# PIC32CM5112SG00100 device description
Architecture: CORTEX-M23; Family: PIC32CM; Series: PIC32CMSG00
Registers are 32-bit, read-write, reset 0x0 unless marked. A register's access mark holds for its fields unless they carry their own. Offsets are from the block's base; [hi:lo] are bit positions.

## HSM — Cryptographic Acceleration Module Lite
Instances: HSM 0x4F000000
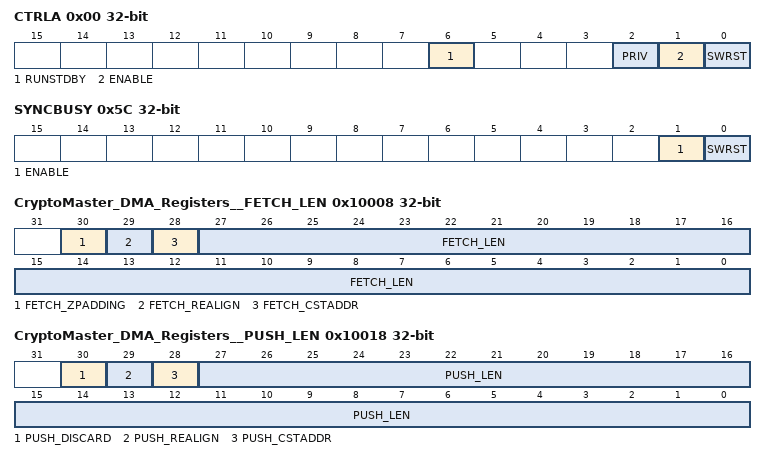
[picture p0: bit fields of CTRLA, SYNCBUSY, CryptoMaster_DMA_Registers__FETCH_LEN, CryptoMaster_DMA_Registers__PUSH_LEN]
0x00 CTRLA — Control Register A
  [6] RUNSTDBY — Run In Standby bit
    0=HSM clock is disabled in Standby Sleep mode, clock requests are de-asserted after any pending bus transactions or requests are completed; 1=If enabled, the HSM clock remains requested in Standby Sleep mode
  [2] PRIV — Privileged Access Only - This bit affects all Wrapper and EIP registers.
    0=HSM registers accessible in privileged and unprivileged modes. Master Requests are NOT privileged; 1=HSM registers only accessible in privileged mode. Master Requests are also privileged.
  [1] ENABLE — Macro/Clock Enable bit
    0=HSM clock is not requested and macros is disabled; 1=HSM clock is requested and macro is enabled
  [0] SWRST — Software Reset1 = Reset registers and internal state0 = No effect
0x38 STATUSA ro — STATUS Register A
  [0] OTPLOCK — OTP Lock bit
    1=OTP lock bit set. Device not in IC manufacturing.
0x5C SYNCBUSY ro
  [1] ENABLE — Macro Enable Synchronization Busy
    0=ENABLE synchronization is NOT busy; 1=ENABLE synchronization is busy
  [0] SWRST — Software Reset Synchronization Busy1 = SWRST synchronization is busy0 = SWRST synchronization is NOT busy
0x10000 CryptoMaster_DMA_Registers__FETCH_ADDR_LSB
  [31:0] FETCH_ADDR_LSB
0x10004 CryptoMaster_DMA_Registers__FETCH_ADDR_MSB
  [31:0] FETCH_ADDR_MSB
0x10008 CryptoMaster_DMA_Registers__FETCH_LEN
  [30] FETCH_ZPADDING, [29] FETCH_REALIGN, [28] FETCH_CSTADDR, [27:0] FETCH_LEN
0x1000C CryptoMaster_DMA_Registers__FETCH_TAG
  [31:0] FETCH_TAG
0x10010 CryptoMaster_DMA_Registers__PUSH_ADDR_LSB
  [31:0] PUSH_ADDR_LSB
0x10014 CryptoMaster_DMA_Registers__PUSH_ADDR_MSB
  [31:0] PUSH_ADDR_MSB
0x10018 CryptoMaster_DMA_Registers__PUSH_LEN
  [30] PUSH_DISCARD, [29] PUSH_REALIGN, [28] PUSH_CSTADDR, [27:0] PUSH_LEN
0x1001C CryptoMaster_DMA_Registers__INT_EN
  [5:0] INT_EN
0x10020 CryptoMaster_DMA_Registers__INT_ENSET wo (atomic set of CryptoMaster_DMA_Registers__INT_EN)
  [5:0] INT_ENSET
0x10024 CryptoMaster_DMA_Registers__INT_ENCLR wo (atomic clear of CryptoMaster_DMA_Registers__INT_EN)
  [5:0] INT_ENCLR
0x10028 CryptoMaster_DMA_Registers__INT_STATRAW ro
  [5:0] INT_STATRAW
0x1002C CryptoMaster_DMA_Registers__INT_STAT ro
  [5:0] INT_STAT
0x10030 CryptoMaster_DMA_Registers__INT_STATCLR wo (atomic clear of CryptoMaster_DMA_Registers__INT_STAT)
  [5:0] INT_STATCLR
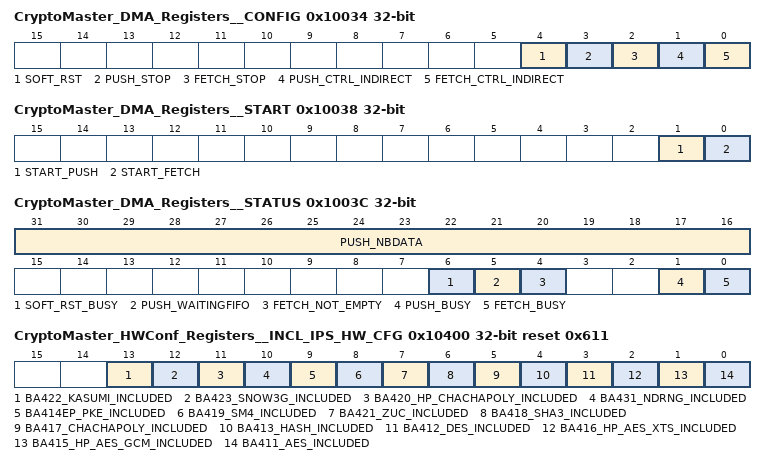
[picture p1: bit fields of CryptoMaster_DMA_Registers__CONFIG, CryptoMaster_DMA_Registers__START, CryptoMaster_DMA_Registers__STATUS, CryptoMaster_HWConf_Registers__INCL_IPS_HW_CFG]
0x10034 CryptoMaster_DMA_Registers__CONFIG
  [4] SOFT_RST, [3] PUSH_STOP, [2] FETCH_STOP, [1] PUSH_CTRL_INDIRECT, [0] FETCH_CTRL_INDIRECT
0x10038 CryptoMaster_DMA_Registers__START wo
  [1] START_PUSH, [0] START_FETCH
0x1003C CryptoMaster_DMA_Registers__STATUS ro
  [31:16] PUSH_NBDATA, [6] SOFT_RST_BUSY, [5] PUSH_WAITINGFIFO, [4] FETCH_NOT_EMPTY, [1] PUSH_BUSY, [0] FETCH_BUSY
0x10400 CryptoMaster_HWConf_Registers__INCL_IPS_HW_CFG ro reset 0x611
  [13] BA422_KASUMI_INCLUDED — Generic g_IncludeKasumi value. BA422-Kasumi IP included if set
  [12] BA423_SNOW3G_INCLUDED — Generic g_IncludeSnow3G value. BA423-Snow3G IP included if set
  [11] BA420_HP_CHACHAPOLY_INCLUDED — Generic g_IncludeHPChachaPoly value. BA420-HP-ChaChaPoly IP included if set
  [10] BA431_NDRNG_INCLUDED — Generic g_IncludeNDRNG value. BA431-NDRNG IP included if set
  [9] BA414EP_PKE_INCLUDED — Generic g_IncludePKE value. BA414EP-PKE IP included if set
  [8] BA419_SM4_INCLUDED — Generic g_IncludeSM4 value. BA419-SM4 IP included if set
  [7] BA421_ZUC_INCLUDED — Generic g_IncludeZUC value. BA421-ZUC IP included if set
  [6] BA418_SHA3_INCLUDED — Generic g_IncludeSHA3 value. BA418-SHA3 IP included if set
  [5] BA417_CHACHAPOLY_INCLUDED — Generic g_IncludeChachaPoly value. BA417-ChaChaPoly IP included if set
  [4] BA413_HASH_INCLUDED — Generic g_IncludeHASH value. BA413-HASH IP included if set
  [3] BA412_DES_INCLUDED — Generic g_IncludeDES value. BA412-3DES IP included if set
  [2] BA416_HP_AES_XTS_INCLUDED — Generic g_IncludeAESXTS value. BA416-HP-AES-XTS IP included if set
  [1] BA415_HP_AES_GCM_INCLUDED — Generic g_IncludeAESGCM value. BA415-HP-AES-GCM IP included if set
  [0] BA411_AES_INCLUDED — Generic g_IncludeAES value. BA411E-AES IP included if set
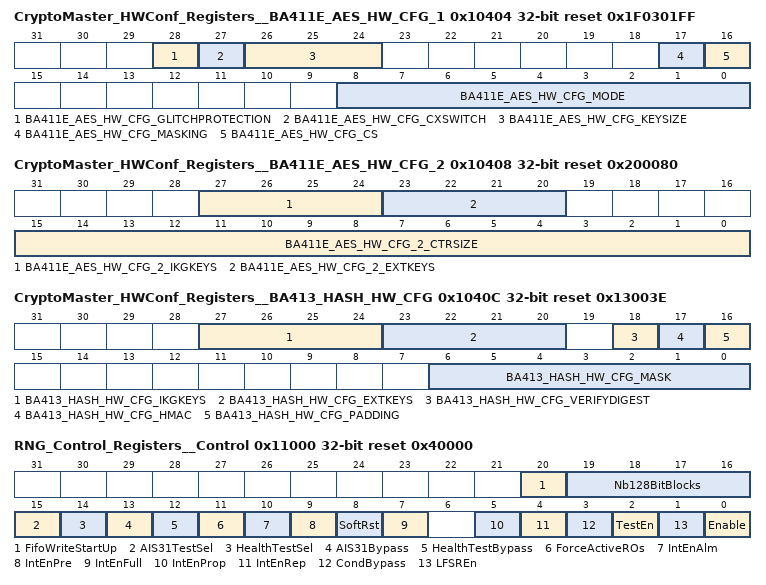
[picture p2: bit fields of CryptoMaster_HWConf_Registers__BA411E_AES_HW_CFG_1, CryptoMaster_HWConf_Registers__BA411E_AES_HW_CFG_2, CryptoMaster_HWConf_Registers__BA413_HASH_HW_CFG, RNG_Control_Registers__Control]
0x10404 CryptoMaster_HWConf_Registers__BA411E_AES_HW_CFG_1 ro reset 0x1F0301FF
  [28] BA411E_AES_HW_CFG_GLITCHPROTECTION — Generic g_GlitchProtection value. BA411E-AES engine configuration.
  [27] BA411E_AES_HW_CFG_CXSWITCH — Generic g_CxSwitch value. BA411E-AES engine configuration.
  [26:24] BA411E_AES_HW_CFG_KEYSIZE — Generic g_Keysize value. BA411E-AES engine configuration.
  [17] BA411E_AES_HW_CFG_MASKING — Generic g_UseMasking value. BA411E-AES engine configuration.
  [16] BA411E_AES_HW_CFG_CS — Generic g_CS value. BA411E-AES engine configuration.
  [8:0] BA411E_AES_HW_CFG_MODE — Generic g_AesModesPoss value. BA411E-AES engine configuration.
0x10408 CryptoMaster_HWConf_Registers__BA411E_AES_HW_CFG_2 ro reset 0x200080 — Generic g_CtrSize value. BA411E-AES engine configuration.
  [27:24] BA411E_AES_HW_CFG_2_IKGKEYS — Generic g_IKG_nb_AES_keys value. BA411E-AES engine configuration.
  [23:20] BA411E_AES_HW_CFG_2_EXTKEYS — Generic g_Ext_nb_AES_keys value. BA411E-AES engine configuration.
  [15:0] BA411E_AES_HW_CFG_2_CTRSIZE — Generic g_CtrSize value. BA411E-AES engine configuration.
0x1040C CryptoMaster_HWConf_Registers__BA413_HASH_HW_CFG ro reset 0x13003E
  [27:24] BA413_HASH_HW_CFG_IKGKEYS — Generic g_IKG_nb_Hash_keys value. BA413-Hash engine configuration.
  [23:20] BA413_HASH_HW_CFG_EXTKEYS — Generic g_Ext_nb_Hash_keys value. BA413-Hash engine configuration.
  [18] BA413_HASH_HW_CFG_VERIFYDIGEST — Generic g_HashVerifyDigest value. BA413-Hash engine configuration.
  [17] BA413_HASH_HW_CFG_HMAC — Generic g_HMAC_enabled value. BA413-Hash engine configuration.
  [16] BA413_HASH_HW_CFG_PADDING — Generic g_HashPadding value. BA413-Hash engine configuration.
  [6:0] BA413_HASH_HW_CFG_MASK — Generic g_HashMaskFunc value. BA413-Hash engine configuration.
0x10410 CryptoMaster_HWConf_Registers__BA418_SHA3_HW_CFG ro — Generic g_Sha3CtxtEn value. BA418-SHA3 configuration.
  [0] BA418_SHA3_HW_CFG
0x10414 CryptoMaster_HWConf_Registers__BA419_SM4_HW_CFG ro reset 0x1FF — Generic g_SM4ModesPoss value. BA419-SM4 engine configuration.
  [8:0] BA419_SM4_HW_CFG
0x10418 CryptoMaster_HWConf_Registers__BA424_ARIA_HW_CFG ro reset 0x17F — Generic g_aria_modePoss value. BA424-Aria engine configuration.
  [8:0] BA424_ARIA_HW_CFG
0x11000 RNG_Control_Registers__Control reset 0x40000 — Control register
  [20] FifoWriteStartUp — Enable write of the samples in the FIFO during start-up.
  [19:16] Nb128BitBlocks — Number of 128 bit blocks used in AES-CBCMAC post-processing. This value cannot be zero.
  [15] AIS31TestSel — Select input to the AIS31 test module: 0: Before conditioning, 1: After conditioning.
  [14] HealthTestSel — Select input to health test module: 0: Before conditioning, 1: After conditioning.
  [13] AIS31Bypass — Bypass AIS31 tests such that the results of the start-up and online tests do not affect the FSM state.
  [12] HealthTestBypass — Bypass NIST tests such that the results of the start-up and online test do not affect the FSM state.
  [11] ForceActiveROs — Force oscillators to run when FIFO is full.
  [10] IntEnAlm — Interrupt enable for AIS31 noise alarm.
  [9] IntEnPre — Interrupt enable for AIS31 preliminary noise alarm.
  [8] SoftRst — Software reset: 0: Normal mode, 1: The continuous test, the conditioning function and the FIFO are reset. This bit is not cleared automatically.
  [7] IntEnFull — Interrupt enable for FIFO full.
  [5] IntEnProp — Interrupt enable for Adaptive Proportion Test failure (1024-sample window).
  [4] IntEnRep — Interrupt enable for Repetition Count Test failure.
  [3] CondBypass — 0: the conditioning function is used (normal mode), 1: the conditioning function is bypassed (to observe entropy source directly).
  [2] TestEn — Select input for conditioning function and continuous tests: 0: Noise source (normal mode), 1: Test data register (test mode).
  [1] LFSREn — Select between the NDRNG with asynchronous free running oscillators (when '0') and the Pseudo-Random generator with synchronous oscillators for simulation purpose (when '1').
  [0] Enable — Enable the NDRNG.
0x11004 RNG_Control_Registers__FIFOLevel — FIFO level register.
  [31:0] FIFOLevel — Number of 32 bits words of random available in the FIFO. Any write to this register clears the FullInt flag in the Status register.
0x11008 RNG_Control_Registers__FIFOThreshold reset 0x1 — FIFO threshold register.
  [1:0] FIFOThreshold — FIFO level below which the module leaves the idle state to refill the FIFO, expressed in number of 128bit blocks.
0x1100C RNG_Control_Registers__FIFODepth ro reset 0x8 — FIFO depth register.
  [31:0] FIFODepth — Maximum number of 32 bits words that can be stored in the FIFO: 2**g_fifodepth.
0x11010 RNG_Control_Registers__Key0 — Key register (MSB).
0x11014 RNG_Control_Registers__Key1 — Key register.
0x11018 RNG_Control_Registers__Key2 — Key register.
0x1101C RNG_Control_Registers__Key3 — Key register (LSB).
0x11020 RNG_Control_Registers__TestData wo — Test data register.
0x11024 RNG_Control_Registers__RepeatThreshold reset 0x29 — Repetition Test Count Cut-Off value.
  [5:0] RepeatThreshold
0x11028 RNG_Control_Registers__PropThreshold reset 0x319 — Adaptive Proportion Test (1024-sample window) Cut-Off value.
  [9:0] PropThreshold
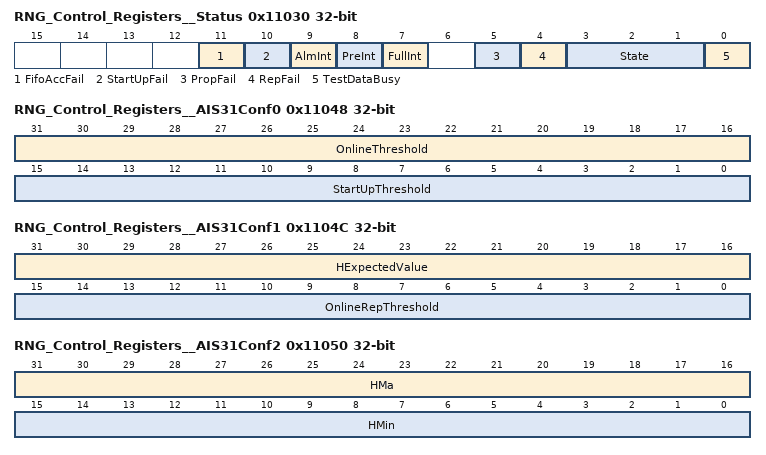
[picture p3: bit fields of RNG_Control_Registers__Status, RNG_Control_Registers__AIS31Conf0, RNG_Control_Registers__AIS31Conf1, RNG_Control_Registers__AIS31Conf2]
0x11030 RNG_Control_Registers__Status — Status register.
  [11] FifoAccFail — Set when a FIFO data read is performed while the NDRNG is disabled AND has its FIFO empty (FIFOLevel = 0).
  [10] StartUpFail — Start-up test failure.
  [9] AlmInt — AIS31 noise alarm interrupt status.
  [8] PreInt — AIS31 preliminary noise alarm interrupt status.
  [7] FullInt — FIFO full status.
  [5] PropFail — NIST-800-90B adaptive Proportion Test (1024-sample window) interrupt status.
  [4] RepFail — NIST-800-90B repetition Count Test interrupt status.
  [3:1] State — State of the control FSM: 000: Reset, 001: Startup, 010: Idle (Rings On), 011: Idle (Rings Off), 100: Fill FIFO, 101: Error, 110: Unused, 111: Unused.
  [0] TestDataBusy — High when data written to TestData register is being processed. (see section 4.7)
0x11034 RNG_Control_Registers__InitWaitVal reset 0xFFFF — Initial wait counter value.
  [15:0] InitWaitVal — Number of clock cycles to wait before sampling data from the noise source.
0x11038 RNG_Control_Registers__DisableOsc0 — Disable oscillator rings #0 to #31.
0x1103C RNG_Control_Registers__DisableOsc1 — Disable oscillator rings #32 to #63.
0x11040 RNG_Control_Registers__SwOffTmrVal reset 0xFFFF — Switch off timer value.
  [15:0] SwOffTmrVal — Number of clk cycles to wait before stopping the rings after the FIFO is full.
0x11044 RNG_Control_Registers__ClkDiv — Sample clock divider.
  [7:0] ClkDiv — Sample clock divider. The frequency at which the outputs of the rings are sampled is given by: Fs=Fpclk/(ClkDiv+1).
0x11048 RNG_Control_Registers__AIS31Conf0 — AIS31 configuration register 0.
  [31:16] OnlineThreshold
  [15:0] StartUpThreshold — Start-up test threshold.
0x1104C RNG_Control_Registers__AIS31Conf1 — AIS31 configuration register 1.
  [31:16] HExpectedValue — Expected history value.
  [15:0] OnlineRepThreshold — Online repeat threshold.
0x11050 RNG_Control_Registers__AIS31Conf2 — AIS31 configuration register 2.
  [31:16] HMa — Maximum allowed history value.
  [15:0] HMin — Minimum allowed history value.
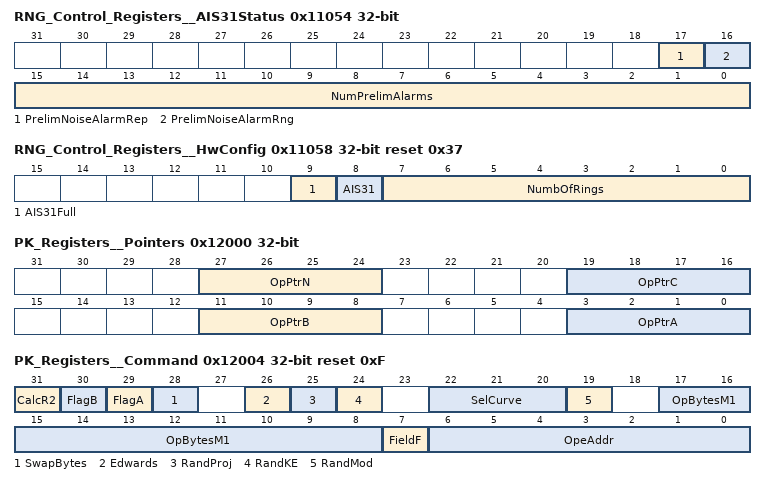
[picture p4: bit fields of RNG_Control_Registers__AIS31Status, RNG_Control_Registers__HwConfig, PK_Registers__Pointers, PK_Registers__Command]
0x11054 RNG_Control_Registers__AIS31Status — AIS31 status register.
  [17] PrelimNoiseAlarmRep — Last preliminary noise alarm occurred due to consecutive high X**2.
  [16] PrelimNoiseAlarmRng — Last preliminary noise alarm occurred due to history value out of range.
  [15:0] NumPrelimAlarms — Number of preliminary noise alarms since counter was last cleared.
0x11058 RNG_Control_Registers__HwConfig ro reset 0x37 — Hardware configuration register.
  [9] AIS31Full — Generic g_AIS31Full value.
  [8] AIS31 — Generic g_AIS31 value.
  [7:0] NumbOfRings — Generic g_NumRings value.
0x12000 PK_Registers__Pointers — Pointers register.
  [27:24] OpPtrN — When executing primitive arithmetic operations, this pointer defines the location where the modulus is located in memory (location 0x0 to 0xF).
  [19:16] OpPtrC — When executing primitive arithmetic operations, this pointer defines the location (0x0 to 0xF) where the result will be stored in memory.
  [11:8] OpPtrB — When executing primitive arithmetic operations, this pointer defines where operand B is located in memory (location 0x0 to 0xF).
  [3:0] OpPtrA — When executing primitive arithmetic operations, this pointer defines where operand A is located in memory (location 0x0 to 0xF).
0x12004 PK_Registers__Command reset 0xF — Command register.
  [31] CalcR2 — This bit indicates if the IP has to calculate R**2 mod N for the next operation. This bit must be set to '1' when a new prime number has been programmed. This bit is used for primitive operations and ignored for the other operations. '0': don't recalculate R**2 mod N '1': re-calculate R**2 mod N
  [30] FlagB — See operation description.
  [29] FlagA — See operation description.
  [28] SwapBytes — Swap the bytes on AHB interface: '0': Native format (little endian) '1': Byte swapped (big endian) See also section 4.2.1. This bit must be programmed before writing/reading any data in data memory.
  [26] Edwards — Enable Edwards curve (see operation description).
  [25] RandProj — Enable randomization of projective coordinates (counter-measure).
  [24] RandKE — Enable randomization of exponent/scalar (counter-measure).
  [22:20] SelCurve — Enable accelerator for specific curve modulus: 0x0: No acceleration (default) 0x1: P256 0x2: P384 0x3: P521 0x4: P192 0x5: Curve25519 0x6: Ed25519 This field has no effect when the optional acceleration hardware is not included.
  [19] RandMod — Enable randomization of modulus (counter-measure).
  [17:8] OpBytesM1 — This field defines the size (= number of bytes minus one) of the operands for the current operation. Possible values are limited by the maximum supported operand size. Examples: - 0x014 -> ECC on curve K-163 - 0x01F -> ECC on curve P-256 - 0x02F -> ECC on curve P-384 - 0x033 -> ECC on curve K-409 - 0x041 -> ECC on curve P-521 - 0x07F -> 1024-bit RSA - 0x09F -> 1280-bit RSA - 0x1FF -> 4096-bit RSA - 0x3FF -> 8192-bit RSA
  [7] FieldF — '0': Field is GF(p) '1': Field is GF(2**m)
  [6:0] OpeAddr — This field defines the operation to be performed. See documentation for more details.
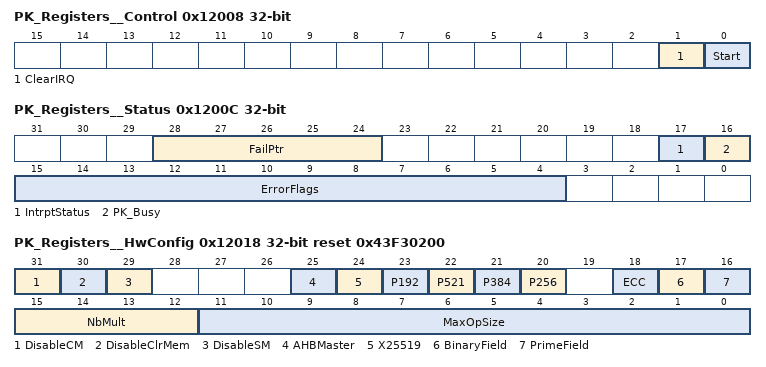
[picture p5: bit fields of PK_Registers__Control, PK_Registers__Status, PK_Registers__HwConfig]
0x12008 PK_Registers__Control wo — Command register.
  [1] ClearIRQ — Writing a '1' clears the IRQ output.
  [0] Start — Writing a '1' starts the processing.
0x1200C PK_Registers__Status ro — Status register.
  [28:24] FailPtr — These bits indicate which data location generated the error flag. They are not available for all error flags.
  [17] IntrptStatus — This bit reflects the IRQ output value. It is set when the operation is finished. It is cleared when the CPU writes the bit 1 of Control Register.
  [16] PK_Busy — This bit reflects the BUSY output value. It is set when the operation starts and it is cleared when the operation is finished.
  [15:4] ErrorFlags — These bits indicate an error condition. They are updated at the end of the operation. They are cleared when starting a new operation. See documentation for more details.
0x12014 PK_Registers__Timer — Timer register.
  [31:1] Timer — Number of core clock cycles.
0x12018 PK_Registers__HwConfig ro reset 0x43F30200 — Hardware configuration register.
  [31] DisableCM — State of DisableCM input (high when counter-measures are disabled).
  [30] DisableClrMem — State of DisableClrMem input (high when automatic clear of the RAM after reset is disabled).
  [29] DisableSM — State of DisableSMx input (high when SM2/SM9 operations are disabled).
  [25] AHBMaster — '0': Memory access through AHB Slave and internally in the PKE. '1': Memory access through AHB Master, outside the PKE.
  [24] X25519 — Support Curve25519/Ed25519 acceleration.
  [23] P192 — Support ECC P192 acceleration.
  [22] P521 — Support ECC P521 acceleration.
  [21] P384 — Support ECC P384 acceleration.
  [20] P256 — Support ECC P256 acceleration.
  [18] ECC — Support RAM error correction.
  [17] BinaryField — Support binary field.
  [16] PrimeField — Support prime field.
  [15:12] NbMult — Number of multipliers: 0x0: 1 multiplier 0x1: 4 multipliers 0x2: 16 multipliers 0x4: 64 multipliers 0x8: 256 multipliers
  [11:0] MaxOpSize — Maximum operand size (number of bytes).
0x1201C PK_Registers__OpSize reset 0x1000 — Operand size register.
  [12:0] OpSize — Operand size (number of bytes): 0x0100: 256 0x0209: 521 0x0800: 2048 0x0C00: 3072 0x1000: 4096 This register is used when the memory is accessed via AHB Master
0x12020 PK_Registers__MemOffset — Memory offset register.
  [31:0] MemOffset — Memory offset for AHB Master
0x12024 PK_Registers__MicroCodeOffset — MicroCode offset register.
  [31:0] MicroCodeOffset — MicroCode offset for AHB Master
